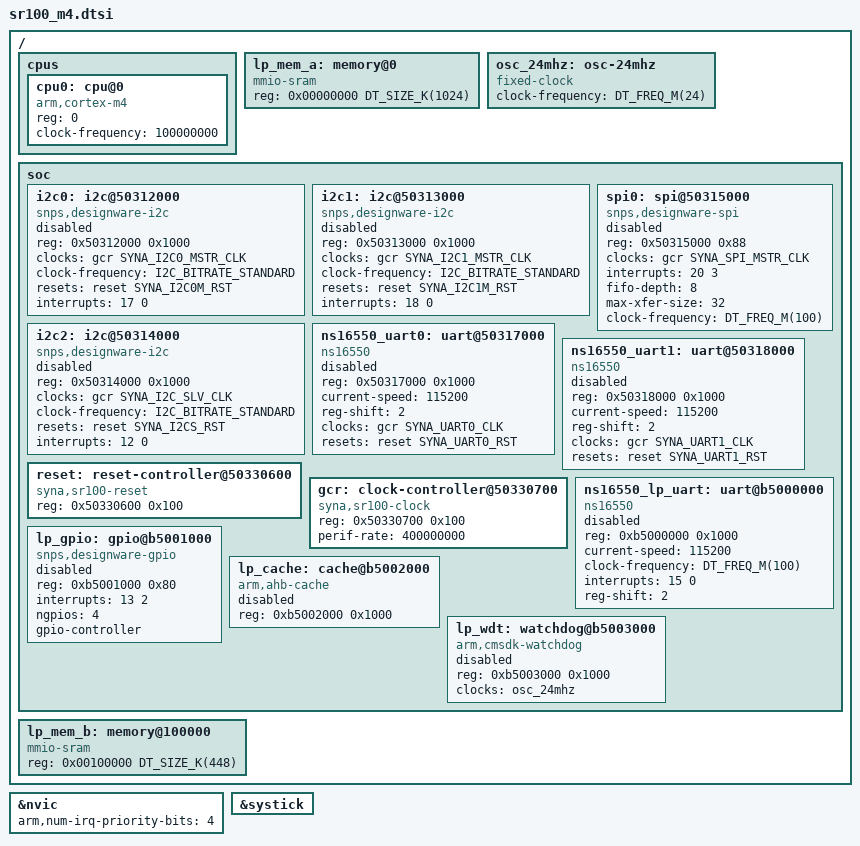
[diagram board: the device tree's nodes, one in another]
/*
 * SPDX-FileCopyrightText: Copyright (c) 2025 Synaptics Incorporated
 *
 * SPDX-License-Identifier: Apache-2.0
 */

/dts-v1/;

#include <mem.h>
#include <freq.h>
#include <arm/armv7-m.dtsi>
#include <zephyr/dt-bindings/gpio/gpio.h>
#include <zephyr/dt-bindings/i2c/i2c.h>
#include <zephyr/dt-bindings/clock/syna_sr100_clock.h>
#include <zephyr/dt-bindings/reset/syna_sr100_reset.h>
#include <zephyr/dt-bindings/memory-attr/memory-attr-arm.h>

/ {
	cpus {
		#address-cells = <1>;
		#size-cells = <0>;

		cpu0: cpu@0 {
			compatible = "arm,cortex-m4";
			reg = <0>;
			device_type = "cpu";
			clock-frequency = <100000000>;
		};
	};

	lp_mem_a: memory@0 {
		compatible = "mmio-sram";
		reg = <0x00000000 DT_SIZE_K(1024)>;
		ranges = <0x0 0x00000000 DT_SIZE_K(1024)>;
		#address-cells = <1>;
		#size-cells = <1>;
	};

	osc_24mhz: osc-24mhz {
		compatible = "fixed-clock";
		#clock-cells = <0>;
		clock-frequency = <DT_FREQ_M(24)>;
		status = "okay";
	};

	soc {
		i2c0: i2c@50312000 {
			compatible = "snps,designware-i2c";
			reg = <0x50312000 0x1000>;
			#address-cells = <1>;
			#size-cells = <0>;
			clocks = <&gcr SYNA_I2C0_MSTR_CLK>;
			clock-frequency = <I2C_BITRATE_STANDARD>;
			resets = <&reset SYNA_I2C0M_RST>;
			interrupts = <17 0>;
			status = "disabled";
		};

		i2c1: i2c@50313000 {
			compatible = "snps,designware-i2c";
			reg = <0x50313000 0x1000>;
			#address-cells = <1>;
			#size-cells = <0>;
			clocks = <&gcr SYNA_I2C1_MSTR_CLK>;
			clock-frequency = <I2C_BITRATE_STANDARD>;
			resets = <&reset SYNA_I2C1M_RST>;
			interrupts = <18 0>;
			status = "disabled";
		};

		i2c2: i2c@50314000 {
			compatible = "snps,designware-i2c";
			reg = <0x50314000 0x1000>; /* I2C slave */
			#address-cells = <1>;
			#size-cells = <0>;
			clocks = <&gcr SYNA_I2C_SLV_CLK>;
			clock-frequency = <I2C_BITRATE_STANDARD>;
			resets = <&reset SYNA_I2CS_RST>;
			interrupts = <12 0>;
			status = "disabled";
		};

		spi0: spi@50315000 {
			compatible = "snps,designware-spi";
			reg = <0x50315000 0x88>;
			#address-cells = <1>;
			#size-cells = <0>;
			clocks = <&gcr SYNA_SPI_MSTR_CLK>;
			interrupts = <20 3>;
			fifo-depth = <8>;
			max-xfer-size = <32>;
			clock-frequency = <DT_FREQ_M(100)>;
			status = "disabled";
		};

		ns16550_uart0: uart@50317000 {
			compatible = "ns16550";
			reg = <0x50317000 0x1000>;
			current-speed = <115200>;
			reg-shift = <2>;
			clocks = <&gcr SYNA_UART0_CLK>;
			resets = <&reset SYNA_UART0_RST>;
			status = "disabled";
		};

		ns16550_uart1: uart@50318000 {
			compatible = "ns16550";
			reg = <0x50318000 0x1000>;
			current-speed = <115200>;
			reg-shift = <2>;
			clocks = <&gcr SYNA_UART1_CLK>;
			resets = <&reset SYNA_UART1_RST>;
			status = "disabled";
		};

		reset: reset-controller@50330600 {
			compatible = "syna,sr100-reset";
			reg = <0x50330600 0x100>;
			#reset-cells = <1>;
			status = "okay";
		};

		gcr: clock-controller@50330700 {
			compatible = "syna,sr100-clock";
			reg = <0x50330700 0x100>;
			perif-rate = <400000000>;
			#clock-cells = <1>;
			status = "okay";
		};

		ns16550_lp_uart: uart@b5000000 {
			compatible = "ns16550";
			reg = <0xb5000000 0x1000>;
			current-speed = <115200>;
			clock-frequency = <DT_FREQ_M(100)>;
			interrupts = <15 0>;
			reg-shift = <2>;
			status = "disabled";
		};

		lp_gpio: gpio@b5001000 {
			compatible = "snps,designware-gpio";
			reg = <0xb5001000 0x80>;
			#address-cells = <1>;
			#size-cells = <0>;
			interrupts = <13 2>;
			ngpios = <4>;
			gpio-controller;
			#gpio-cells = <2>;
			status = "disabled";
		};

		lp_cache: cache@b5002000 {
			compatible = "arm,ahb-cache";
			reg = <0xb5002000 0x1000>;
			status = "disabled";
		};

		lp_wdt: watchdog@b5003000 {
			compatible = "arm,cmsdk-watchdog";
			reg = <0xb5003000 0x1000>;
			clocks = <&osc_24mhz>;
			status = "disabled";
		};
	};

	lp_mem_b: memory@100000 {
		compatible = "mmio-sram";
		reg = <0x00100000 DT_SIZE_K(448)>;
		ranges = <0x0 0x00100000 DT_SIZE_K(448)>;
		#address-cells = <1>;
		#size-cells = <1>;
	};
};

&nvic {
	arm,num-irq-priority-bits = <4>;
};

&systick {
	status = "okay";
};
